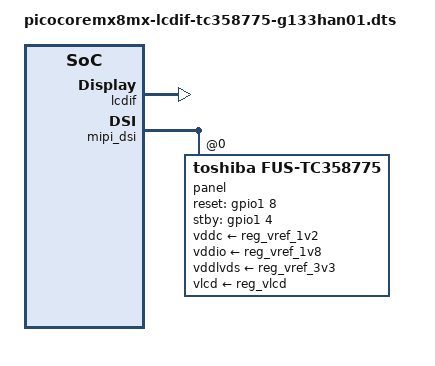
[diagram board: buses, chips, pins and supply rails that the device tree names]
/*
 * Copyright (C) 2019 F&S Elektronik Systeme GmbH
 *
 * This program is free software; you can redistribute it and/or modify
 * it under the terms of the GNU General Public License version 2 as
 * published by the Free Software Foundation.
 */

#define CONFIG_PICOCOREMX8MX_MIPI_DSI_LVDS

#include "picocoremx8mx.dts"


/ {
	backlight_ldb {
		pwms = <&pwm2 0 2000000 0>;
		brightness-levels = < 23 39 55 71 87 103 119 135 151 167 183
		     199 215 231 239 255>;
		default-brightness-level = <14>;
	};


};

&lcdif {
	status = "okay";
	/* important to overwrite max-res otherwise DRM lcdif will fail to find a suitable connector */
	max-res = <4096>, <4096>;
};

&mipi_dsi {
	status = "okay";

	panel@0{
		status = "okay";
		compatible = "toshiba,fus-tc358775";
		reg = <0>;
		pinctrl-names = "default";
		pinctrl-0 = <&pinctrl_mipi_dsi_en>;

		reset-gpios = <&gpio1 8 GPIO_ACTIVE_HIGH>;
		stby-gpios  = <&gpio1 4 GPIO_ACTIVE_HIGH>;

		vddc-supply = <&reg_vref_1v2>;
		vddio-supply = <&reg_vref_1v8>;
		vddlvds-supply = <&reg_vref_3v3>;
		vlcd-supply = <&reg_vlcd>;

		dsi,format = <0x0>; /* MIPI_DSI_FMT_RGB888 */
		dsi,lanes = <4>;
		dsi,flags = <0xB>; /* MIPI_DSI_MODE_VIDEO MIPI_DSI_MODE_VIDEO_BURST MIPI_DSI_MODE_VIDEO_AUTO_VERT */
		refresh-rate = <60>;
                rotate = <0>;

		panel-width-mm = <154>;
		panel-height-mm = <85>;

		reg,address = <
				/* dsi basic parameters in lp mode */
				0x013c 0x0114 0x0164 0x0168
				0x016C 0x0170 0x0134 0x0210
				0x0104 0x0204
				/* Timing and mode settings */
				0x0450 0x0454 0x0458 0x045C
				0x0460 0x0464 0x04A0 0x04A0 0x0504
				/* color mapping settings	*/
				0x0480 0x0484 0x0488 0x048C 0x0490
				0x0494 0x0498
				 /* LVDS enable */
                0x049C>;
		reg,value = <
				/* dsi basic parameters in lp mode */
				0xA000C 0x8 0xD 0xD
				0xD	0xD 0x1F 0x1F
				0x1 0x1
				/* Timing and mode settings */
				0x03200120 0x750038 0x4D0780 0x130013
				0xB0438 0x1 0x448006 0x48006 0x4
				/* color mapping settings	*/
				0x5040302 0xA070106 0x9080C0B 0x120F0E0D 0x14131110
				0x1B171615 0x01A1918
				0x00000263>;

		display-timings {
			native-mode = <&timing0>;

			timing0: G133HAN01 {
				clock-frequency = <150000000>;
				hactive = <1920>;
				vactive = <1080>;
				hback-porch = <20>;
				hfront-porch = <159>;
				hsync-len = <70>;
				vback-porch = <37>;
				vfront-porch = <11>;
				vsync-len = <1>;
				pixelclk-active = <0>;
			};
		};
	};
};

